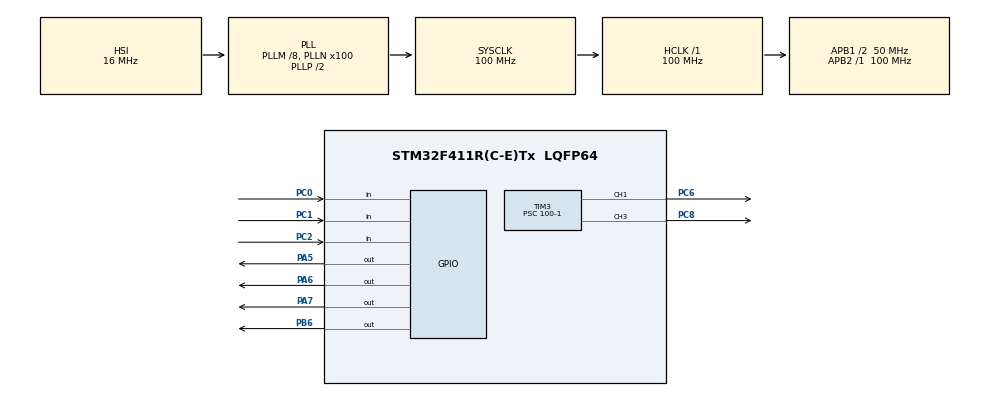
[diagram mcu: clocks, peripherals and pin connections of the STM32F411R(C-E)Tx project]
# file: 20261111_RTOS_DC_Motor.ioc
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FREERTOS.Queues01=btnQue,16,uint32_t,0,Dynamic,NULL,NULL
FREERTOS.Tasks01=defaultTask,0,128,StartDefaultTask,Default,NULL,Dynamic,NULL,NULL;MotorTask,0,128,StartMotorTask,Default,NULL,Dynamic,NULL,NULL;ButtonTask,0,128,StartButtonTask,Default,NULL,Dynamic,NULL,NULL
FREERTOS.configUSE_NEWLIB_REENTRANT=1
Mcu.Family=STM32F4
Mcu.Name=STM32F411R(C-E)Tx
Mcu.Package=LQFP64
NVIC.PriorityGroup=NVIC_PRIORITYGROUP_4
NVIC.TIM1_UP_TIM10_IRQn=true\:15\:0\:false\:false\:true\:false\:false\:true\:true
NVIC.TimeBase=TIM1_UP_TIM10_IRQn
NVIC.TimeBaseIP=TIM10
PA13.Mode=Serial_Wire
PA13.Signal=SYS_JTMS-SWDIO
PA14.Mode=Serial_Wire
PA14.Signal=SYS_JTCK-SWCLK
PA5.Signal=GPIO_Output
PA6.Signal=GPIO_Output
PA7.Signal=GPIO_Output
PB6.Signal=GPIO_Output
PC0.Signal=GPIO_Input
PC1.Signal=GPIO_Input
PC2.Signal=GPIO_Input
PC6.Signal=S_TIM3_CH1
PC8.Signal=S_TIM3_CH3
PH0\ -\ OSC_IN.Mode=HSE-External-Oscillator
PH0\ -\ OSC_IN.Signal=RCC_OSC_IN
PH1\ -\ OSC_OUT.Mode=HSE-External-Oscillator
PH1\ -\ OSC_OUT.Signal=RCC_OSC_OUT
ProjectManager.HeapSize=0x200
ProjectManager.StackSize=0x400
ProjectManager.TargetToolchain=STM32CubeIDE
RCC.48MHZClocksFreq_Value=50000000
RCC.AHBFreq_Value=100000000
RCC.APB1CLKDivider=RCC_HCLK_DIV2
RCC.APB1Freq_Value=50000000
RCC.APB1TimFreq_Value=100000000
RCC.APB2Freq_Value=100000000
RCC.APB2TimFreq_Value=100000000
RCC.CortexFreq_Value=100000000
RCC.HCLKFreq_Value=100000000
RCC.HSE_VALUE=8000000
RCC.HSI_VALUE=16000000
RCC.LSE_VALUE=32768
RCC.PLLM=8
RCC.PLLN=100
RCC.SYSCLKFreq_VALUE=100000000
RCC.SYSCLKSource=RCC_SYSCLKSOURCE_PLLCLK
RCC.VCOOutputFreq_Value=200000000
SH.S_TIM3_CH1.0=TIM3_CH1,PWM Generation1 CH1
SH.S_TIM3_CH3.0=TIM3_CH3,PWM Generation3 CH3
TIM3.AutoReloadPreload=TIM_AUTORELOAD_PRELOAD_ENABLE
TIM3.Channel-PWM\ Generation1\ CH1=TIM_CHANNEL_1
TIM3.Channel-PWM\ Generation3\ CH3=TIM_CHANNEL_3
TIM3.Period=1000-1
TIM3.Prescaler=100-1
VP_FREERTOS_VS_CMSIS_V1.Mode=CMSIS_V1
VP_SYS_VS_tim10.Mode=TIM10
VP_TIM3_VS_ClockSourceINT.Mode=Internal
board=custom

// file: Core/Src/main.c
/* USER CODE BEGIN Header */
/**
  ******************************************************************************
  * @file           : main.c
  * @brief          : Main program body
  ******************************************************************************
  * @attention
  *
  * Copyright (c) 2026 STMicroelectronics.
  * All rights reserved.
  *
  * This software is licensed under terms that can be found in the LICENSE file
  * in the root directory of this software component.
  * If no LICENSE file comes with this software, it is provided AS-IS.
  *
  ******************************************************************************
  */
/* USER CODE END Header */
#include "main.h"
#include "cmsis_os.h"
#include "tim.h"
#include "gpio.h"

void SystemClock_Config(void);
void MX_FREERTOS_Init(void);

int main(void)
{

  /* MCU Configuration--------------------------------------------------------*/

  /* Reset of all peripherals, Initializes the Flash interface and the Systick. */
  HAL_Init();

  /* Configure the system clock */
  SystemClock_Config();

  /* Initialize all configured peripherals */
  MX_GPIO_Init();
  MX_TIM3_Init();

  /* Call init function for freertos objects (in cmsis_os2.c) */
  MX_FREERTOS_Init();

  /* Start scheduler */
  osKernelStart();

  /* We should never get here as control is now taken by the scheduler */

  /* Infinite loop */
  while (1)
  {

  }
}

void SystemClock_Config(void)
{
  RCC_OscInitTypeDef RCC_OscInitStruct = {0};
  RCC_ClkInitTypeDef RCC_ClkInitStruct = {0};

  /** Configure the main internal regulator output voltage
  */
  __HAL_RCC_PWR_CLK_ENABLE();
  __HAL_PWR_VOLTAGESCALING_CONFIG(PWR_REGULATOR_VOLTAGE_SCALE1);

  /** Initializes the RCC Oscillators according to the specified parameters
  * in the RCC_OscInitTypeDef structure.
  */
  RCC_OscInitStruct.OscillatorType = RCC_OSCILLATORTYPE_HSI;
  RCC_OscInitStruct.HSIState = RCC_HSI_ON;
  RCC_OscInitStruct.HSICalibrationValue = RCC_HSICALIBRATION_DEFAULT;
  RCC_OscInitStruct.PLL.PLLState = RCC_PLL_ON;
  RCC_OscInitStruct.PLL.PLLSource = RCC_PLLSOURCE_HSI;
  RCC_OscInitStruct.PLL.PLLM = 8;
  RCC_OscInitStruct.PLL.PLLN = 100;
  RCC_OscInitStruct.PLL.PLLP = RCC_PLLP_DIV2;
  RCC_OscInitStruct.PLL.PLLQ = 4;
  if (HAL_RCC_OscConfig(&RCC_OscInitStruct) != HAL_OK)
  {
    Error_Handler();
  }

  /** Initializes the CPU, AHB and APB buses clocks
  */
  RCC_ClkInitStruct.ClockType = RCC_CLOCKTYPE_HCLK|RCC_CLOCKTYPE_SYSCLK
                              |RCC_CLOCKTYPE_PCLK1|RCC_CLOCKTYPE_PCLK2;
  RCC_ClkInitStruct.SYSCLKSource = RCC_SYSCLKSOURCE_PLLCLK;
  RCC_ClkInitStruct.AHBCLKDivider = RCC_SYSCLK_DIV1;
  RCC_ClkInitStruct.APB1CLKDivider = RCC_HCLK_DIV2;
  RCC_ClkInitStruct.APB2CLKDivider = RCC_HCLK_DIV1;

  if (HAL_RCC_ClockConfig(&RCC_ClkInitStruct, FLASH_LATENCY_3) != HAL_OK)
  {
    Error_Handler();
  }
}

void HAL_TIM_PeriodElapsedCallback(TIM_HandleTypeDef *htim)
{
  if (htim->Instance == TIM10)
  {
    HAL_IncTick();
  }
}

void Error_Handler(void)
{
  __disable_irq();
  while (1)
  {
  }
}

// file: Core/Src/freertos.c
/* USER CODE BEGIN Header */
/**
 ******************************************************************************
 * File Name          : freertos.c
 * Description        : Code for freertos applications
 ******************************************************************************
 * @attention
 *
 * Copyright (c) 2026 STMicroelectronics.
 * All rights reserved.
 *
 * This software is licensed under terms that can be found in the LICENSE file
 * in the root directory of this software component.
 * If no LICENSE file comes with this software, it is provided AS-IS.
 *
 ******************************************************************************
 */
/* USER CODE END Header */

#include "FreeRTOS.h"
#include "task.h"
#include "main.h"
#include "cmsis_os.h"

/* USER CODE BEGIN Includes */
#include "ap/task/button_task/button_task.h"
#include "ap/task/motor_control_task/motor_control_task.h"
/* USER CODE END Includes */

/* USER CODE BEGIN Variables */

extern TIM_HandleTypeDef htim3;

/* USER CODE END Variables */
osThreadId defaultTaskHandle;
osThreadId MotorTaskHandle;
osThreadId ButtonTaskHandle;
osMessageQId btnQueHandle;

void StartDefaultTask(void const * argument);
void StartMotorTask(void const * argument);
void StartButtonTask(void const * argument);

void MX_FREERTOS_Init(void); /* (MISRA C 2004 rule 8.1) */

/* GetIdleTaskMemory prototype (linked to static allocation support) */
void vApplicationGetIdleTaskMemory( StaticTask_t **ppxIdleTaskTCBBuffer, StackType_t **ppxIdleTaskStackBuffer, uint32_t *pulIdleTaskStackSize );

/* USER CODE BEGIN GET_IDLE_TASK_MEMORY */
static StaticTask_t xIdleTaskTCBBuffer;
static StackType_t xIdleStack[configMINIMAL_STACK_SIZE];

void vApplicationGetIdleTaskMemory( StaticTask_t **ppxIdleTaskTCBBuffer, StackType_t **ppxIdleTaskStackBuffer, uint32_t *pulIdleTaskStackSize )
{
	*ppxIdleTaskTCBBuffer = &xIdleTaskTCBBuffer;
	*ppxIdleTaskStackBuffer = &xIdleStack[0];
	*pulIdleTaskStackSize = configMINIMAL_STACK_SIZE;
	/* place for user code */
}
/* USER CODE END GET_IDLE_TASK_MEMORY */

void MX_FREERTOS_Init(void) {

	/* Create the queue(s) */
	/* definition and creation of btnQue */
	osMessageQDef(btnQue, 16, uint32_t);
	btnQueHandle = osMessageCreate(osMessageQ(btnQue), NULL);

	/* Create the thread(s) */
	/* definition and creation of defaultTask */
	osThreadDef(defaultTask, StartDefaultTask, osPriorityNormal, 0, 128);
	defaultTaskHandle = osThreadCreate(osThread(defaultTask), NULL);

	/* definition and creation of MotorTask */
	osThreadDef(MotorTask, StartMotorTask, osPriorityNormal, 0, 128);
	MotorTaskHandle = osThreadCreate(osThread(MotorTask), NULL);

	/* definition and creation of ButtonTask */
	osThreadDef(ButtonTask, StartButtonTask, osPriorityNormal, 0, 128);
	ButtonTaskHandle = osThreadCreate(osThread(ButtonTask), NULL);

}

void StartDefaultTask(void const * argument)
{
	for(;;)
	{
		osDelay(1);
	}
}

void StartMotorTask(void const * argument)
{
	/* USER CODE BEGIN StartMotorTask */
	motor_control_task_init();
	/* Infinite loop */
	for(;;)
	{
		motor_control_task();
		osDelay(10);
	}
	/* USER CODE END StartMotorTask */
}

void StartButtonTask(void const * argument)
{
	/* USER CODE BEGIN StartButtonTask */
	button_task_init();

	/* Infinite loop */
	for(;;)
	{
		button_task();
		osDelay(10);
	}
	/* USER CODE END StartButtonTask */
}
